# MDR1986VK01 register map
File version: 1.0.2
Registers are 32-bit, read-write, no defined reset value unless marked. A register's access mark holds for its fields unless they carry their own. Offsets are from the block's base; [hi:lo] are bit positions; {n}, {i} and the like mark numbered series; 'fields as' and 'values as' point back to an identical list.

## MDR_DAC0 — MDR_DAC0 description
Base 0x400AA000
Same registers: MDR_DAC1 0x400AB000, MDR_DAC2 0x400AC000, MDR_DAC3 0x400AD000
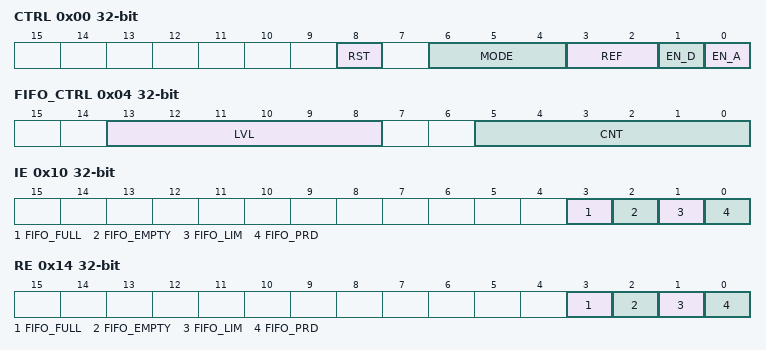
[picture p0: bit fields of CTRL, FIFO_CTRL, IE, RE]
0x00 CTRL — CTRL description
  [8] RST — RST description
  [6:4] MODE — MODE description
  [3:2] REF — REF description
  [1] EN_D — EN_D description
  [0] EN_A — EN_A description
0x04 FIFO_CTRL — FIFO_CTRL description
  [13:8] LVL — LVL description
  [5:0] CNT — CNT description
0x08 PRD — PRD description
0x0C CNT — CNT description
0x10 IE — IE description
  [3] FIFO_FULL — FIFO_FULL description
  [2] FIFO_EMPTY — FIFO_EMPTY description
  [1] FIFO_LIM — FIFO_LIM description
  [0] FIFO_PRD — FIFO_PRD description
0x14 RE — RE description
  fields as IE
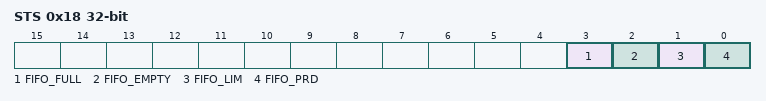
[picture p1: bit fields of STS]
0x18 STS — STS description
  fields as IE
0x1C DATA — DATA description
  [11:0] DATA

## MDR_COMP0 — MDR_COMP0 description
Base 0x400AE000
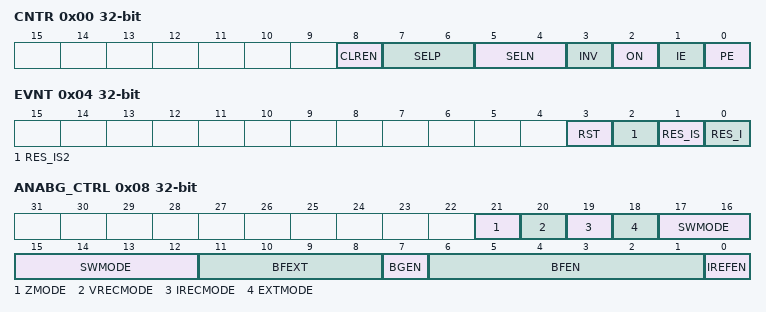
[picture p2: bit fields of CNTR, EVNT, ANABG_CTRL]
0x00 CNTR — CNTR description
  [8] CLREN — CLREN description
  [7:6] SELP — SELP description
  [5:4] SELN — SELN description
  [3] INV — INV description
  [2] ON — ON description
  [1] IE — IE description
  [0] PE — PE description
0x04 EVNT — EVNT description
  [3] RST — RST description
  [2] RES_IS2 — RES_IS2 description
  [1] RES_IS — RES_IS description
  [0] RES_I — RES_I description
0x08 ANABG_CTRL — ANABG_CTRL description
  [21] ZMODE — ZMODE description
  [20] VRECMODE — VRECMODE description
  [19] IRECMODE — IRECMODE description
  [18] EXTMODE — EXTMODE description
  [17:12] SWMODE — SWMODE description
  [11:8] BFEXT — BFEXT description
  [7] BGEN — BGEN description
  [6:1] BFEN — BFEN description
  [0] IREFEN — IREFEN description

## MDR_COMP1 — MDR_COMP1 description
Base 0x400AF000
Registers as MDR_COMP0, without ANABG_CTRL.

## MDR_COMP2 — MDR_COMP2 description
Base 0x400B0000
Registers as MDR_COMP0, without ANABG_CTRL.

## MDR_COMP3 — MDR_COMP3 description
Base 0x400B1000
Registers as MDR_COMP0, without ANABG_CTRL.

## MDR_I2C — MDR_I2C description
Base 0x400B2000
0x00 I2C_PRL — I2C_PRL description
  [7:0] PR — PR description
0x04 I2C_PRH — I2C_PRH description
  [7:0] PR — PR description
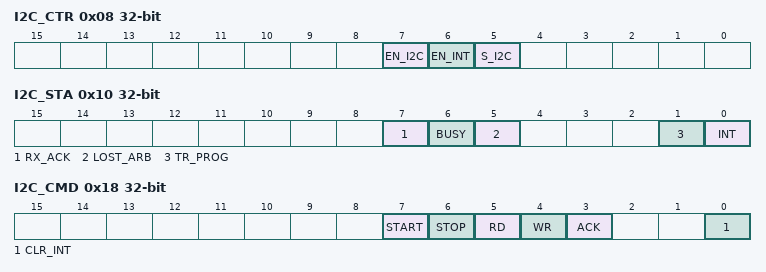
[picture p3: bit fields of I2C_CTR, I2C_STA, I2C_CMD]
0x08 I2C_CTR — I2C_CTR description
  [7] EN_I2C — EN_I2C description
  [6] EN_INT — EN_INT description
  [5] S_I2C — S_I2C description
0x0C I2C_RXD — I2C_RXD description
  [7:0] RXD — RXD description
0x10 I2C_STA — I2C_STA description
  [7] RX_ACK — RX_ACK description
  [6] BUSY — BUSY description
  [5] LOST_ARB — LOST_ARB description
  [1] TR_PROG — TR_PROG description
  [0] INT — INT description
0x14 I2C_TXD — I2C_TXD description
  [7:0] TXD — TXD description
0x18 I2C_CMD — I2C_CMD description
  [7] START — START description
  [6] STOP — STOP description
  [5] RD — RD description
  [4] WR — WR description
  [3] ACK — ACK description
  [0] CLR_INT — CLR_INT description

## MDR_SDIO — MDR_SDIO description
Base 0x400B5000
0x00 POWER — POWER description
  [1:0] PWRCTRL — PWRCTRL description
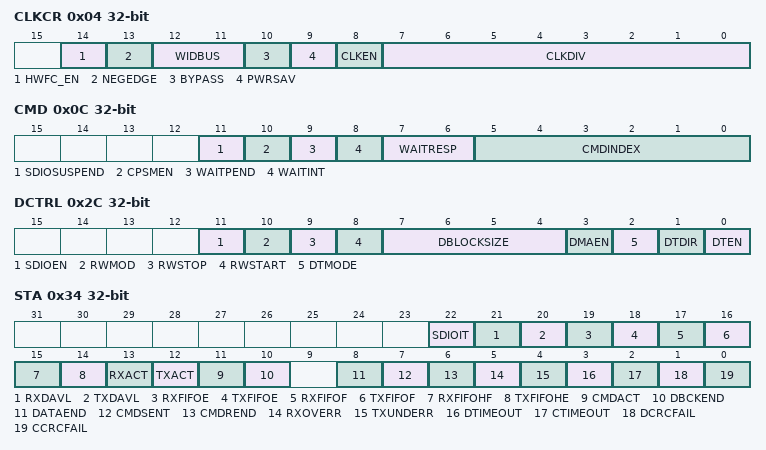
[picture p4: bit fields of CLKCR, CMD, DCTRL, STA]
0x04 CLKCR — CLKCR description
  [14] HWFC_EN — HWFC_EN description
  [13] NEGEDGE — NEGEDGE description
  [12:11] WIDBUS — WIDBUS description
  [10] BYPASS — BYPASS description
  [9] PWRSAV — PWRSAV description
  [8] CLKEN — CLKEN description
  [7:0] CLKDIV — CLKDIV description
0x08 ARG — ARG description
0x0C CMD — CMD description
  [11] SDIOSUSPEND — SDIOSUSPEND description
  [10] CPSMEN — CPSMEN description
  [9] WAITPEND — WAITPEND description
  [8] WAITINT — WAITINT description
  [7:6] WAITRESP — WAITRESP description
  [5:0] CMDINDEX — CMDINDEX description
0x10 RESPCMD — RESPCMD description
  [5:0] RESPCMD
{0x10+4i} RESP{i} (i=1..4) — RESP{i} description
0x24 DTIMER — DTIMER description
0x28 DLEN — DLEN description
  [24:0] DATALENGTH — DATALENGTH description
0x2C DCTRL — DCTRL description
  [11] SDIOEN — SDIOEN description
  [10] RWMOD — RWMOD description
  [9] RWSTOP — RWSTOP description
  [8] RWSTART — RWSTART description
  [7:4] DBLOCKSIZE — DBLOCKSIZE description
  [3] DMAEN — DMAEN description
  [2] DTMODE — DTMODE description
  [1] DTDIR — DTDIR description
  [0] DTEN — DTEN description
0x30 DCOUNT — DCOUNT description
  [24:0] DATACOUNT — DATACOUNT description
0x34 STA — STA description
  [22] SDIOIT — SDIOIT description
  [21] RXDAVL — RXDAVL description
  [20] TXDAVL — TXDAVL description
  [19] RXFIFOE — RXFIFOE description
  [18] TXFIFOE — TXFIFOE description
  [17] RXFIFOF — RXFIFOF description
  [16] TXFIFOF — TXFIFOF description
  [15] RXFIFOHF — RXFIFOHF description
  [14] TXFIFOHE — TXFIFOHE description
  [13] RXACT — RXACT description
  [12] TXACT — TXACT description
  [11] CMDACT — CMDACT description
  [10] DBCKEND — DBCKEND description
  [8] DATAEND — DATAEND description
  [7] CMDSENT — CMDSENT description
  [6] CMDREND — CMDREND description
  [5] RXOVERR — RXOVERR description
  [4] TXUNDERR — TXUNDERR description
  [3] DTIMEOUT — DTIMEOUT description
  [2] CTIMEOUT — CTIMEOUT description
  [1] DCRCFAIL — DCRCFAIL description
  [0] CCRCFAIL — CCRCFAIL description
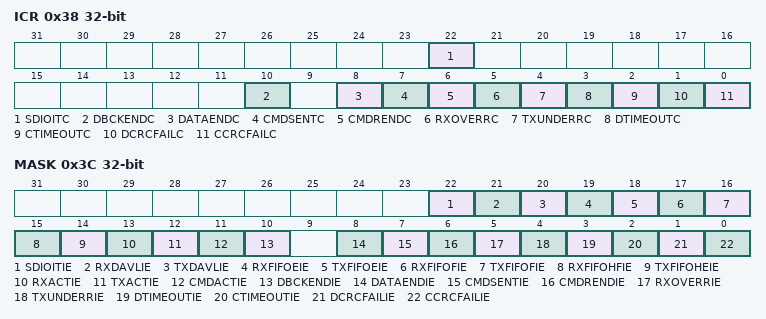
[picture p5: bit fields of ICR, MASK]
0x38 ICR — ICR description
  [22] SDIOITC — SDIOITC description
  [10] DBCKENDC — DBCKENDC description
  [8] DATAENDC — DATAENDC description
  [7] CMDSENTC — CMDSENTC description
  [6] CMDRENDC — CMDRENDC description
  [5] RXOVERRC — RXOVERRC description
  [4] TXUNDERRC — TXUNDERRC description
  [3] DTIMEOUTC — DTIMEOUTC description
  [2] CTIMEOUTC — CTIMEOUTC description
  [1] DCRCFAILC — DCRCFAILC description
  [0] CCRCFAILC — CCRCFAILC description
0x3C MASK — MASK description
  [22] SDIOITIE — SDIOITIE description
  [21] RXDAVLIE — RXDAVLIE description
  [20] TXDAVLIE — TXDAVLIE description
  [19] RXFIFOEIE — RXFIFOEIE description
  [18] TXFIFOEIE — TXFIFOEIE description
  [17] RXFIFOFIE — RXFIFOFIE description
  [16] TXFIFOFIE — TXFIFOFIE description
  [15] RXFIFOHFIE — RXFIFOHFIE description
  [14] TXFIFOHEIE — TXFIFOHEIE description
  [13] RXACTIE — RXACTIE description
  [12] TXACTIE — TXACTIE description
  [11] CMDACTIE — CMDACTIE description
  [10] DBCKENDIE — DBCKENDIE description
  [8] DATAENDIE — DATAENDIE description
  [7] CMDSENTIE — CMDSENTIE description
  [6] CMDRENDIE — CMDRENDIE description
  [5] RXOVERRIE — RXOVERRIE description
  [4] TXUNDERRIE — TXUNDERRIE description
  [3] DTIMEOUTIE — DTIMEOUTIE description
  [2] CTIMEOUTIE — CTIMEOUTIE description
  [1] DCRCFAILIE — DCRCFAILIE description
  [0] CCRCFAILIE — CCRCFAILIE description
0x48 FIFOCNT — FIFOCNT description
  [23:0] FIFOCOUNT — FIFOCOUNT description
0x80 FIFO — FIFO description

## MDR_CRC — MDR_CRC description
Base 0x400B6000
0x00 DR — CRC Data register
0x04 IDR 8-bit — CRC Independent data register
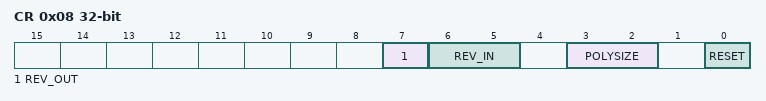
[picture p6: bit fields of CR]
0x08 CR — CRC Control register
  [7] REV_OUT — Reverse output data
  [6:5] REV_IN — Reverse input data
  [3:2] POLYSIZE — Polynomial size
  [0] RESET — reset bit
0x10 INIT — Initial CRC value register
0x14 POL — CRC polynomial register

## GATE0 — GATE0 description
Base 0x21030000
Same registers: GATE1 0x21030080
0x00 FIFO_OP_TO_SF — FIFO opened core -> safe core data register
0x04 FIFO_SF_TO_OP — FIFO safe core -> opened core data register
0x08 FIFO_LEVELS — FIFO control levels register
0x0C FIFO_INT_MASK — FIFO interruptions mask register
0x10 FIFO_INT_SOURCE — FIFO interruption source register
{0x14+4i} REG{i:02} (i=0..7) — In/out data register{i:02} r/w
{0x14+4i} REG{i:02} (i=8..15) — In/out data register{i:02} r/o
0x54 REGS_BUSY — Input data registers busyness indicator
0x58 REGS_INT_MASK — Data registers interruptions mask register
0x5C REGS_INT_SOURCE — Data registers interruption source register
